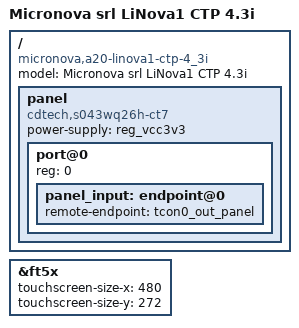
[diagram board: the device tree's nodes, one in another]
// SPDX-License-Identifier: (GPL-2.0+ OR MIT)
/*
 * Device Tree Source for LiNova1 CTP 4.3" HMI
 *
 * Copyright (C) 2018 Micronova srl
 *   Author: Giulio Benetti <giulio.benetti@micronovasrl.com>
 */

/dts-v1/;
#include "sun7i-a20-linova1.dtsi"

/ {
	model = "Micronova srl LiNova1 CTP 4.3i";
	compatible = "micronova,a20-linova1-ctp-4_3i", "allwinner,sun7i-a20";

	panel: panel {
		compatible = "cdtech,s043wq26h-ct7", "simple-panel";
		power-supply = <&reg_vcc3v3>;
		#address-cells = <1>;
		#size-cells = <0>;

		port@0 {
			reg = <0>;
			#address-cells = <1>;
			#size-cells = <0>;

			panel_input: endpoint@0 {
				remote-endpoint = <&tcon0_out_panel>;
			};
		};
	};
};

&ft5x {
	touchscreen-size-x = <480>;
	touchscreen-size-y = <272>;
};
